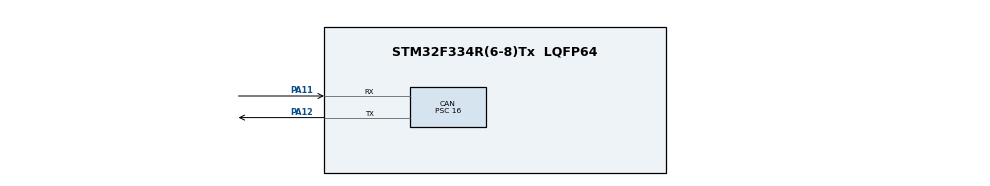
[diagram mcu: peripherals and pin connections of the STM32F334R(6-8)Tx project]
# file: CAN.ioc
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CAN.BS1=CAN_BS1_2TQ
CAN.BS2=CAN_BS2_1TQ
CAN.CalculateBaudRate=500000
CAN.CalculateTimeBit=2000
CAN.CalculateTimeQuantum=500.0
CAN.Prescaler=16
Mcu.Family=STM32F3
Mcu.Name=STM32F334R(6-8)Tx
Mcu.Package=LQFP64
NVIC.PriorityGroup=NVIC_PRIORITYGROUP_0
PA11.Mode=CAN_Activate
PA11.Signal=CAN_RX
PA12.Mode=CAN_Activate
PA12.Signal=CAN_TX
PF0\ /\ OSC_IN.Mode=HSE-External-Oscillator
PF0\ /\ OSC_IN.Signal=RCC_OSC_IN
PF1\ /\ OSC_OUT.Mode=HSE-External-Oscillator
PF1\ /\ OSC_OUT.Signal=RCC_OSC_OUT
ProjectManager.HeapSize=0x200
ProjectManager.StackSize=0x400
ProjectManager.TargetToolchain=STM32CubeIDE
RCC.AHBFreq_Value=64000000
RCC.APB1CLKDivider=RCC_HCLK_DIV2
RCC.APB1Freq_Value=32000000
RCC.APB1TimFreq_Value=64000000
RCC.APB2Freq_Value=64000000
RCC.APB2TimFreq_Value=64000000
RCC.CortexFreq_Value=64000000
RCC.FLatency-AdvancedSettings=FLASH_LATENCY_2
RCC.HCLKFreq_Value=64000000
RCC.HSE_VALUE=8000000
RCC.HSI_VALUE=8000000
RCC.PLLMUL=RCC_PLL_MUL16
RCC.SYSCLKFreq_VALUE=64000000
RCC.SYSCLKSourceVirtual=RCC_SYSCLKSOURCE_PLLCLK
board=NUCLEO-F334R8

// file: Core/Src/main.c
/* USER CODE BEGIN Header */
/**
  ******************************************************************************
  * @file           : main.c
  * @brief          : Main program body
  ******************************************************************************
  * @attention
  *
  * Copyright (c) 2022 STMicroelectronics.
  * All rights reserved.
  *
  * This software is licensed under terms that can be found in the LICENSE file
  * in the root directory of this software component.
  * If no LICENSE file comes with this software, it is provided AS-IS.
  *
  ******************************************************************************
  */
/* USER CODE END Header */
#include "main.h"

CAN_HandleTypeDef hcan;

/* USER CODE BEGIN PV */

CAN_TxHeaderTypeDef TX_Header;
CAN_FilterTypeDef FI_Header;
CAN_RxHeaderTypeDef RX_Header;

/* USER CODE END PV */

void SystemClock_Config(void);
static void MX_GPIO_Init(void);
static void MX_CAN_Init(void);
/* USER CODE BEGIN PFP */
void filter_config(void);
void CAN_TX(void);
/* USER CODE END PFP */

/* USER CODE BEGIN 0 */
char tdata[5]="12345";
uint32_t TxMailbox;
char rdata[5];
/* USER CODE END 0 */

int main(void)
{

  /* MCU Configuration--------------------------------------------------------*/

  /* Reset of all peripherals, Initializes the Flash interface and the Systick. */
  HAL_Init();

  /* Configure the system clock */
  SystemClock_Config();

  /* Initialize all configured peripherals */
  MX_GPIO_Init();
  MX_CAN_Init();
  /* USER CODE BEGIN 2 */
  HAL_CAN_WakeUp(&hcan);
  filter_config();
  HAL_CAN_Start( &hcan);
  /* USER CODE END 2 */

  /* Infinite loop */
  while (1)
  {

    /* USER CODE BEGIN 3 */
	  CAN_TX();
	//  CAN_RX();
  }
  /* USER CODE END 3 */
}

void SystemClock_Config(void)
{
  RCC_OscInitTypeDef RCC_OscInitStruct = {0};
  RCC_ClkInitTypeDef RCC_ClkInitStruct = {0};

  /** Initializes the RCC Oscillators according to the specified parameters
  * in the RCC_OscInitTypeDef structure.
  */
  RCC_OscInitStruct.OscillatorType = RCC_OSCILLATORTYPE_HSI;
  RCC_OscInitStruct.HSIState = RCC_HSI_ON;
  RCC_OscInitStruct.HSICalibrationValue = RCC_HSICALIBRATION_DEFAULT;
  RCC_OscInitStruct.PLL.PLLState = RCC_PLL_NONE;
  if (HAL_RCC_OscConfig(&RCC_OscInitStruct) != HAL_OK)
  {
    Error_Handler();
  }

  /** Initializes the CPU, AHB and APB buses clocks
  */
  RCC_ClkInitStruct.ClockType = RCC_CLOCKTYPE_HCLK|RCC_CLOCKTYPE_SYSCLK
                              |RCC_CLOCKTYPE_PCLK1|RCC_CLOCKTYPE_PCLK2;
  RCC_ClkInitStruct.SYSCLKSource = RCC_SYSCLKSOURCE_HSI;
  RCC_ClkInitStruct.AHBCLKDivider = RCC_SYSCLK_DIV1;
  RCC_ClkInitStruct.APB1CLKDivider = RCC_HCLK_DIV1;
  RCC_ClkInitStruct.APB2CLKDivider = RCC_HCLK_DIV1;

  if (HAL_RCC_ClockConfig(&RCC_ClkInitStruct, FLASH_LATENCY_0) != HAL_OK)
  {
    Error_Handler();
  }
}

static void MX_CAN_Init(void)
{

  hcan.Instance = CAN;
  hcan.Init.Prescaler = 16;
  hcan.Init.Mode = CAN_MODE_NORMAL;
  hcan.Init.SyncJumpWidth = CAN_SJW_1TQ;
  hcan.Init.TimeSeg1 = CAN_BS1_2TQ;
  hcan.Init.TimeSeg2 = CAN_BS2_1TQ;
  hcan.Init.TimeTriggeredMode = DISABLE;
  hcan.Init.AutoBusOff = DISABLE;
  hcan.Init.AutoWakeUp = DISABLE;
  hcan.Init.AutoRetransmission = ENABLE;
  hcan.Init.ReceiveFifoLocked = DISABLE;
  hcan.Init.TransmitFifoPriority = DISABLE;
  if (HAL_CAN_Init(&hcan) != HAL_OK)
  {
    Error_Handler();
  }
  /* USER CODE BEGIN CAN_Init 2 */
  // hcan.Instance->MCR  &= ~ ( CAN_MCR_SLEEP);

  /* USER CODE END CAN_Init 2 */

}

static void MX_GPIO_Init(void)
{

  /* GPIO Ports Clock Enable */
  __HAL_RCC_GPIOF_CLK_ENABLE();
  __HAL_RCC_GPIOA_CLK_ENABLE();

}

/* USER CODE BEGIN 4 */

void  CAN_TX()
{
	TX_Header.DLC= 4;
	TX_Header.StdId=0x041;
	TX_Header.IDE=CAN_ID_STD;
	TX_Header.RTR=CAN_RTR_DATA;
	if( HAL_CAN_AddTxMessage(&hcan, &TX_Header, tdata, &TxMailbox )!= HAL_OK)
	{
		Error_Handler();
	}
		while(HAL_CAN_IsTxMessagePending(&hcan,TxMailbox)) ;
	//CAN_RX();
}

void filter_config()
{
	FI_Header.FilterActivation=CAN_FILTER_ENABLE;
	FI_Header.FilterBank= 0;
	FI_Header.FilterFIFOAssignment=CAN_FILTER_FIFO0;
	FI_Header.FilterIdHigh= 0x041 << 5;
	FI_Header.FilterIdLow=0x0000;

	/*FI_Header.FilterMaskIdHigh=0;
	FI_Header.FilterMaskIdLow=0x0000;*/
	FI_Header.FilterMode=CAN_FILTERMODE_IDLIST;
	FI_Header.FilterScale= CAN_FILTERSCALE_32BIT;

	HAL_CAN_ConfigFilter(&hcan, &FI_Header);
}

void CAN_RX()
{
	while(!HAL_CAN_GetRxFifoFillLevel( &hcan, CAN_RX_FIFO0));

	if(HAL_CAN_GetRxMessage(&hcan, CAN_RX_FIFO0, &RX_Header,rdata)!= HAL_OK)
	{
		Error_Handler();
	}
	if ( rdata[0]==0x22) // Read data by identifier
		{
		//	if ( RX_Header.DLC == 1)
			{
				CAN_TX();
			}

		}
}

/* USER CODE END 4 */

void Error_Handler(void)
{
  __disable_irq();
  while (1)
  {
  }
}
